# PIC32MK0512MCF064 register map
Vendor: Microchip
Registers are 32-bit, read-write, reset 0x0 unless marked. A register's access mark holds for its fields unless they carry their own. Addresses are absolute, and some are shared; only a register's first bit layout is shown; [hi:lo] are bit positions; {n}, {i} and the like mark numbered series.

## PORTB
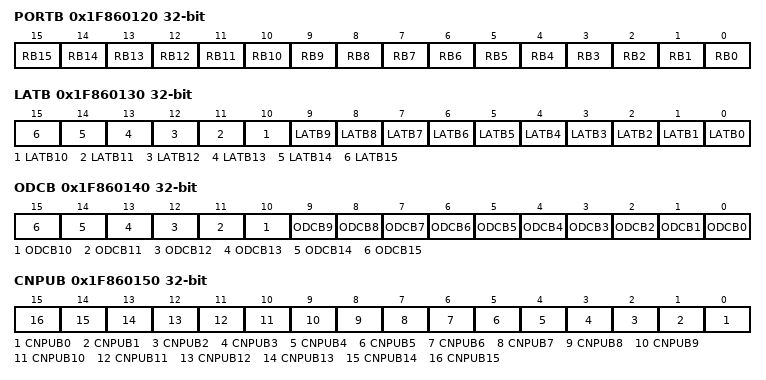
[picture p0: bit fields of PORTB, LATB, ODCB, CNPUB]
0x1F860120 PORTB reset not defined — (power-on value ----------------xxxxxxxxxxxxxxxx)
  [n] RB{n} (n=0..15)
0x1F860130 LATB reset not defined — (power-on value ----------------xxxxxxxxxxxxxxxx)
  [n] LATB{n} (n=0..15)
0x1F860140 ODCB
  [n] ODCB{n} (n=0..15)
0x1F860150 CNPUB
  [n] CNPUB{n} (n=0..15)
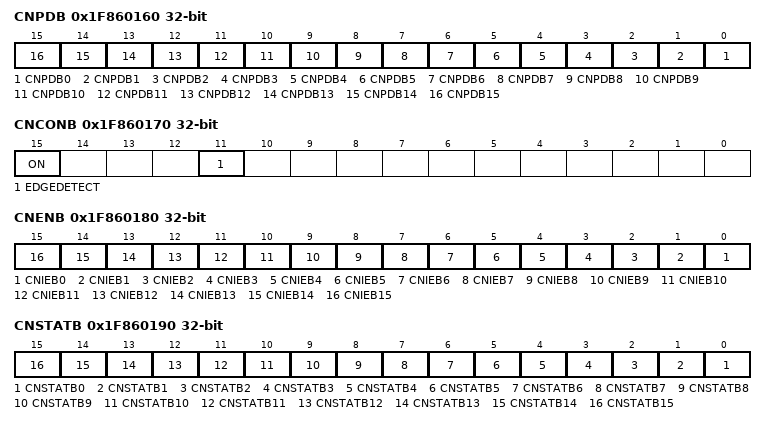
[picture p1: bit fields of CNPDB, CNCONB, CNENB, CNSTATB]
0x1F860160 CNPDB
  [n] CNPDB{n} (n=0..15)
0x1F860170 CNCONB
  [15] ON, [11] EDGEDETECT
0x1F860180 CNENB
  [n] CNIEB{n} (n=0..15)
0x1F860190 CNSTATB
  [n] CNSTATB{n} (n=0..15)
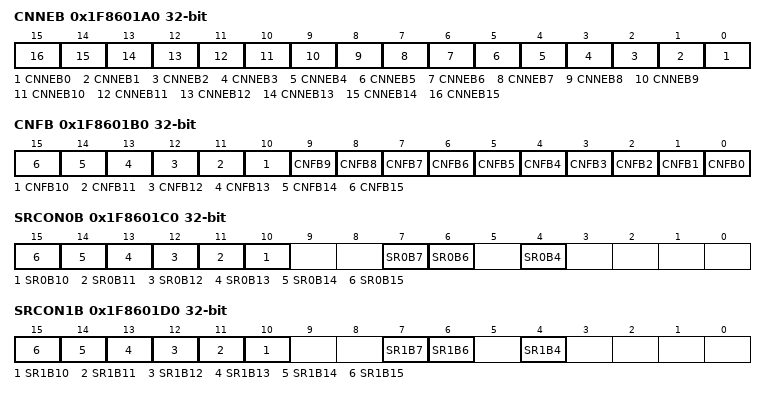
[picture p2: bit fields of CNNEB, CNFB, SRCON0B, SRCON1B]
0x1F8601A0 CNNEB
  [n] CNNEB{n} (n=0..15)
0x1F8601B0 CNFB
  [n] CNFB{n} (n=0..15)
0x1F8601C0 SRCON0B
  [n] SR0B{n} (n=10..15), [7] SR0B7, [6] SR0B6, [4] SR0B4
0x1F8601D0 SRCON1B
  [n] SR1B{n} (n=10..15), [7] SR1B7, [6] SR1B6, [4] SR1B4

## PORTC
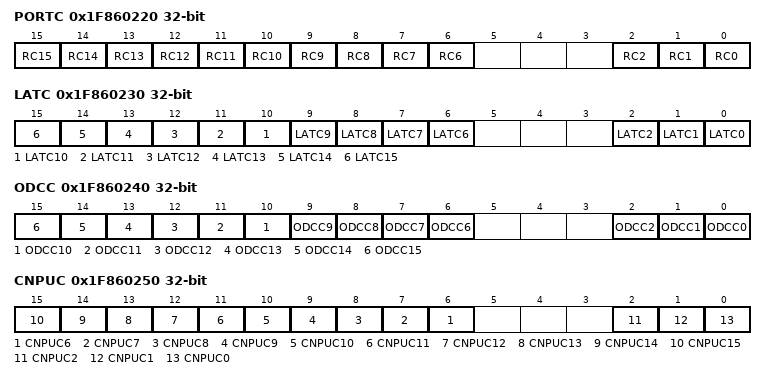
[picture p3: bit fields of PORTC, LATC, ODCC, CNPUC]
0x1F860220 PORTC reset not defined — (power-on value ----------------xxxxxxxxxx---xxx)
  [n] RC{n} (n=6..15), [2] RC2, [1] RC1, [0] RC0
0x1F860230 LATC reset not defined — (power-on value ----------------xxxxxxxxxx---xxx)
  [n] LATC{n} (n=6..15), [2] LATC2, [1] LATC1, [0] LATC0
0x1F860240 ODCC
  [n] ODCC{n} (n=6..15), [2] ODCC2, [1] ODCC1, [0] ODCC0
0x1F860250 CNPUC
  [n] CNPUC{n} (n=6..15), [2] CNPUC2, [1] CNPUC1, [0] CNPUC0
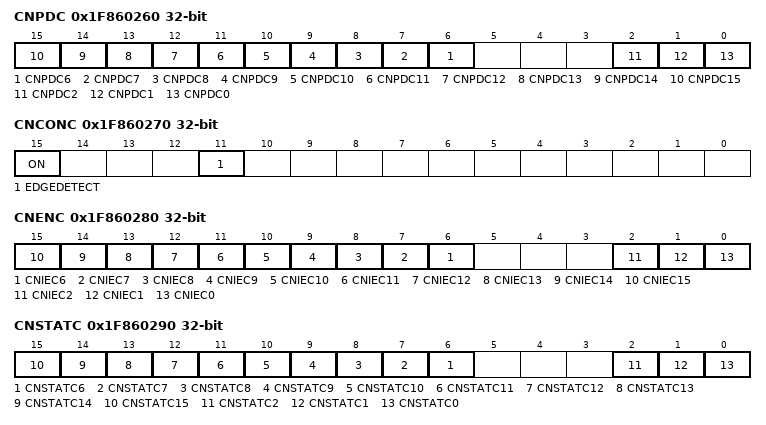
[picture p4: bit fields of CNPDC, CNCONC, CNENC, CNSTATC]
0x1F860260 CNPDC
  [n] CNPDC{n} (n=6..15), [2] CNPDC2, [1] CNPDC1, [0] CNPDC0
0x1F860270 CNCONC
  [15] ON, [11] EDGEDETECT
0x1F860280 CNENC
  [n] CNIEC{n} (n=6..15), [2] CNIEC2, [1] CNIEC1, [0] CNIEC0
0x1F860290 CNSTATC
  [n] CNSTATC{n} (n=6..15), [2] CNSTATC2, [1] CNSTATC1, [0] CNSTATC0
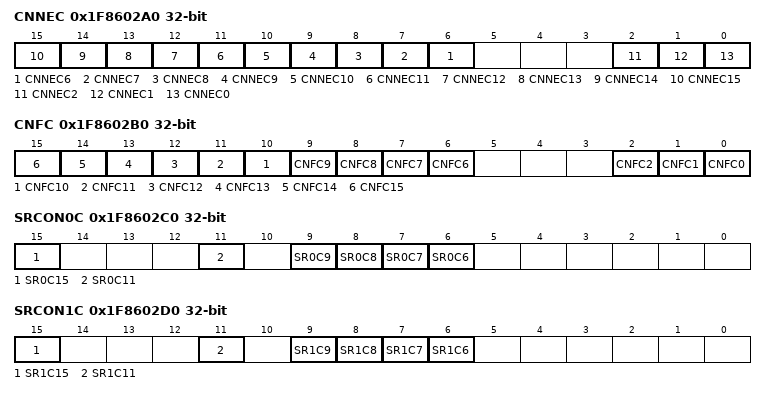
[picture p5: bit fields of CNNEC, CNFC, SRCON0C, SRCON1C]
0x1F8602A0 CNNEC
  [n] CNNEC{n} (n=6..15), [2] CNNEC2, [1] CNNEC1, [0] CNNEC0
0x1F8602B0 CNFC
  [n] CNFC{n} (n=6..15), [2] CNFC2, [1] CNFC1, [0] CNFC0
0x1F8602C0 SRCON0C
  [15] SR0C15, [11] SR0C11, [n] SR0C{n} (n=6..9)
0x1F8602D0 SRCON1C
  [15] SR1C15, [11] SR1C11, [n] SR1C{n} (n=6..9)

## PORTD
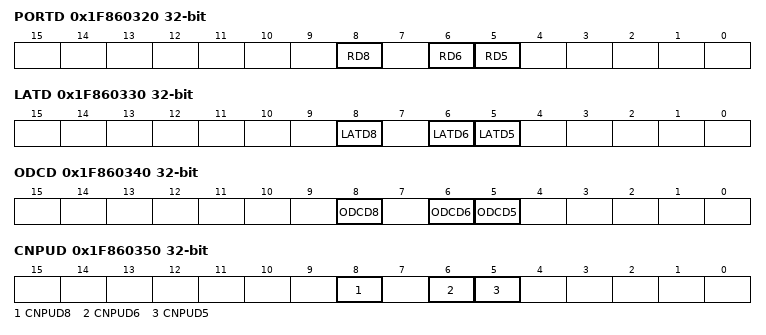
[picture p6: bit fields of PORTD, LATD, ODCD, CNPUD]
0x1F860320 PORTD reset not defined — (power-on value -----------------------x-xx-----)
  [8] RD8, [6] RD6, [5] RD5
0x1F860330 LATD reset not defined — (power-on value -----------------------x-xx-----)
  [8] LATD8, [6] LATD6, [5] LATD5
0x1F860340 ODCD
  [8] ODCD8, [6] ODCD6, [5] ODCD5
0x1F860350 CNPUD
  [8] CNPUD8, [6] CNPUD6, [5] CNPUD5
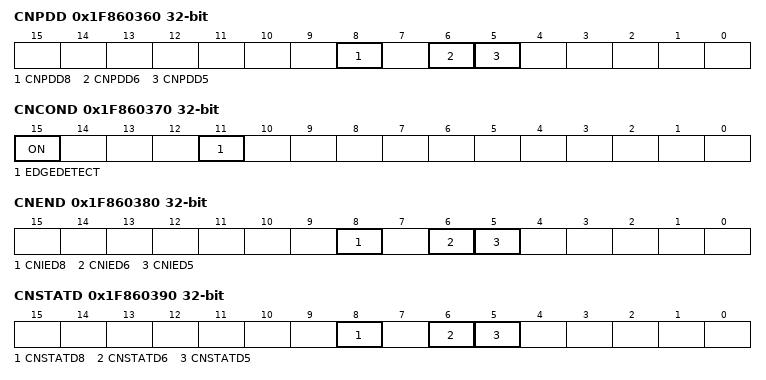
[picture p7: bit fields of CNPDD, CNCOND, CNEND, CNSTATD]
0x1F860360 CNPDD
  [8] CNPDD8, [6] CNPDD6, [5] CNPDD5
0x1F860370 CNCOND
  [15] ON, [11] EDGEDETECT
0x1F860380 CNEND
  [8] CNIED8, [6] CNIED6, [5] CNIED5
0x1F860390 CNSTATD
  [8] CNSTATD8, [6] CNSTATD6, [5] CNSTATD5
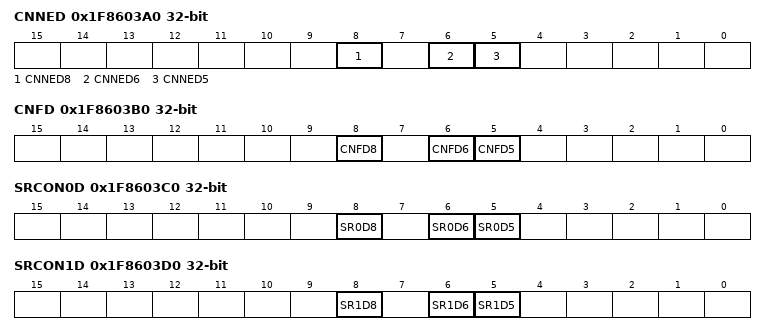
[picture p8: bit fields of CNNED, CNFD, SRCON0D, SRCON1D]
0x1F8603A0 CNNED
  [8] CNNED8, [6] CNNED6, [5] CNNED5
0x1F8603B0 CNFD
  [8] CNFD8, [6] CNFD6, [5] CNFD5
0x1F8603C0 SRCON0D
  [8] SR0D8, [6] SR0D6, [5] SR0D5
0x1F8603D0 SRCON1D
  [8] SR1D8, [6] SR1D6, [5] SR1D5

## PORTE
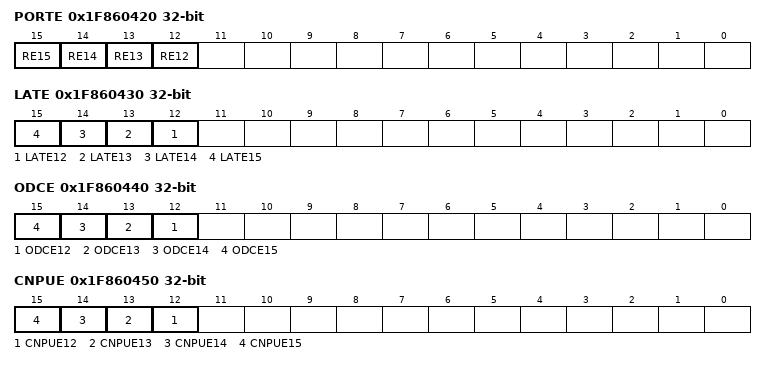
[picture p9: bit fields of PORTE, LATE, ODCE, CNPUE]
0x1F860420 PORTE reset not defined — (power-on value ----------------xxxx------------)
  [n] RE{n} (n=12..15)
0x1F860430 LATE reset not defined — (power-on value ----------------xxxx------------)
  [n] LATE{n} (n=12..15)
0x1F860440 ODCE
  [n] ODCE{n} (n=12..15)
0x1F860450 CNPUE
  [n] CNPUE{n} (n=12..15)
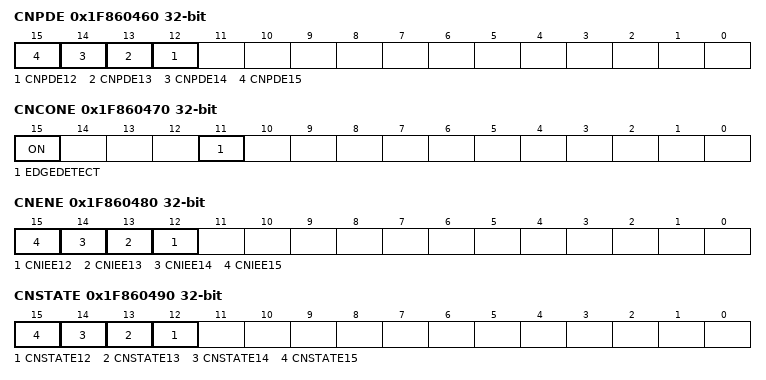
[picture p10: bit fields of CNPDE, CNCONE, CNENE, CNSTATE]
0x1F860460 CNPDE
  [n] CNPDE{n} (n=12..15)
0x1F860470 CNCONE
  [15] ON, [11] EDGEDETECT
0x1F860480 CNENE
  [n] CNIEE{n} (n=12..15)
0x1F860490 CNSTATE
  [n] CNSTATE{n} (n=12..15)
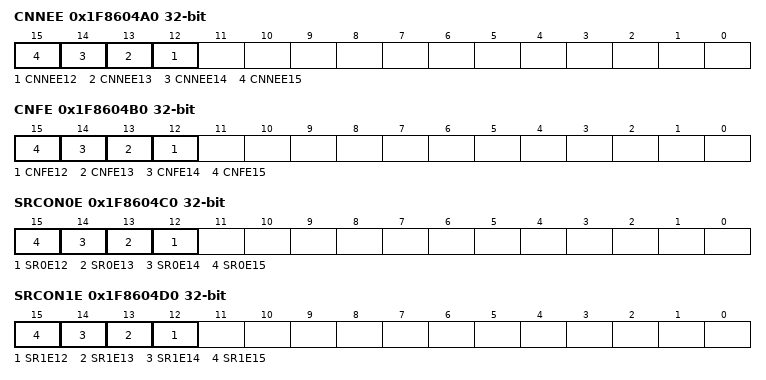
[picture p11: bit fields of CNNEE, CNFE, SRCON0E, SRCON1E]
0x1F8604A0 CNNEE
  [n] CNNEE{n} (n=12..15)
0x1F8604B0 CNFE
  [n] CNFE{n} (n=12..15)
0x1F8604C0 SRCON0E
  [n] SR0E{n} (n=12..15)
0x1F8604D0 SRCON1E
  [n] SR1E{n} (n=12..15)

## PORTF
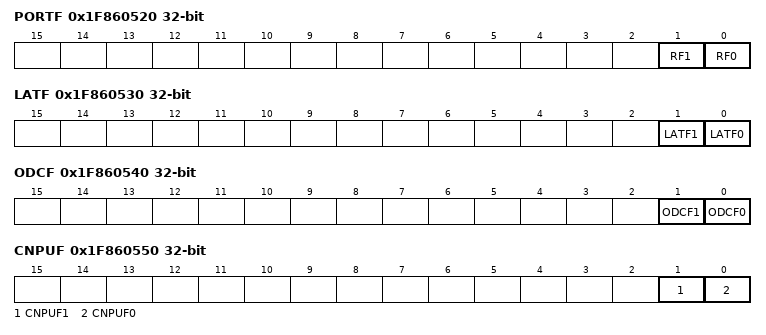
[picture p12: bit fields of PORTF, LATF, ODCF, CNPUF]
0x1F860520 PORTF reset not defined — (power-on value ------------------------------xx)
  [1] RF1, [0] RF0
0x1F860530 LATF reset not defined — (power-on value ------------------------------xx)
  [1] LATF1, [0] LATF0
0x1F860540 ODCF
  [1] ODCF1, [0] ODCF0
0x1F860550 CNPUF
  [1] CNPUF1, [0] CNPUF0
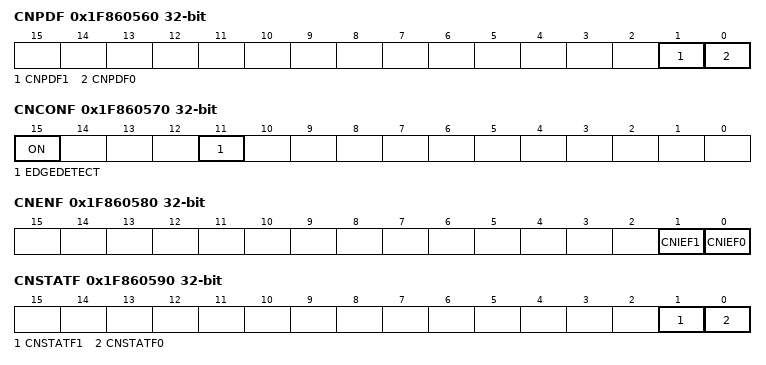
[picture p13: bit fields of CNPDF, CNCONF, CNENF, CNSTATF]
0x1F860560 CNPDF
  [1] CNPDF1, [0] CNPDF0
0x1F860570 CNCONF
  [15] ON, [11] EDGEDETECT
0x1F860580 CNENF
  [1] CNIEF1, [0] CNIEF0
0x1F860590 CNSTATF
  [1] CNSTATF1, [0] CNSTATF0
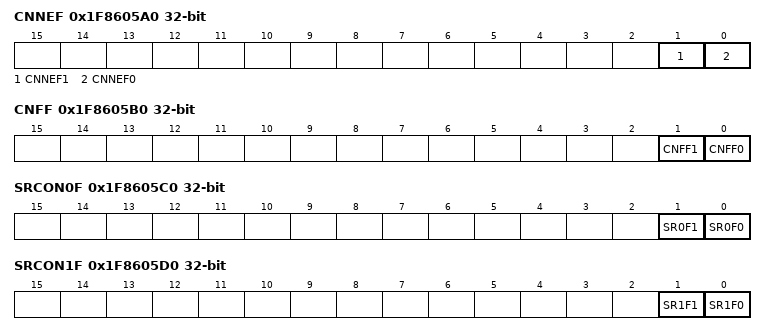
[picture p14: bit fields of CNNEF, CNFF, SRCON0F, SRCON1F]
0x1F8605A0 CNNEF
  [1] CNNEF1, [0] CNNEF0
0x1F8605B0 CNFF
  [1] CNFF1, [0] CNFF0
0x1F8605C0 SRCON0F
  [1] SR0F1, [0] SR0F0
0x1F8605D0 SRCON1F
  [1] SR1F1, [0] SR1F0
